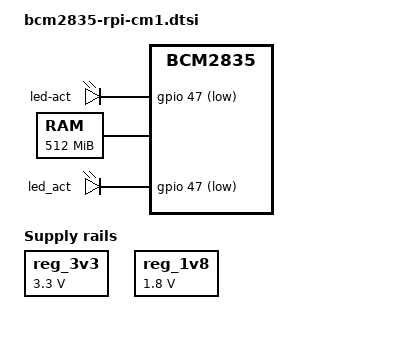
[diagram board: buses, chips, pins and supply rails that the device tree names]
// SPDX-License-Identifier: GPL-2.0
/dts-v1/;
#include "bcm2835.dtsi"
#include "bcm2835-rpi.dtsi"
#include "bcm2835-rpi-common.dtsi"
#include "bcm283x-rpi-led-deprecated.dtsi"

/ {
	leds {
		led-act {
			gpios = <&gpio 47 GPIO_ACTIVE_LOW>;
		};
	};

	memory@0 {
		device_type = "memory";
		reg = <0 0x20000000>;
	};

	reg_3v3: fixed-regulator {
		compatible = "regulator-fixed";
		regulator-name = "3V3";
		regulator-min-microvolt = <3300000>;
		regulator-max-microvolt = <3300000>;
		regulator-always-on;
	};

	reg_1v8: fixed-regulator {
		compatible = "regulator-fixed";
		regulator-name = "1V8";
		regulator-min-microvolt = <1800000>;
		regulator-max-microvolt = <1800000>;
		regulator-always-on;
	};
};

&led_act {
	gpios = <&gpio 47 GPIO_ACTIVE_LOW>;
};

&sdhost {
	non-removable;
	vmmc-supply = <&reg_3v3>;
	vqmmc-supply = <&reg_1v8>;
};
